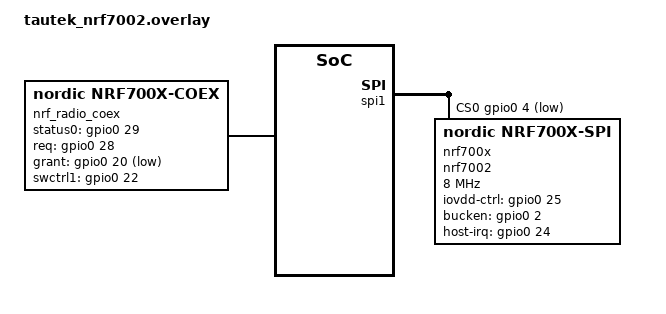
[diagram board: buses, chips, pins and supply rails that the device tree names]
#include <freq.h>

/ {
	nrf_radio_coex: nrf7002-coex {
		status = "okay";
		compatible = "nordic,nrf700x-coex";
		status0-gpios = <&gpio0 29 GPIO_ACTIVE_HIGH>;       /* D2 */
		req-gpios = <&gpio0 28 GPIO_ACTIVE_HIGH>;   /* D3 */
		grant-gpios = <&gpio0 20 (GPIO_PULL_DOWN | GPIO_ACTIVE_LOW)>;    /* D4 */
		swctrl1-gpios = <&gpio0 22 GPIO_ACTIVE_HIGH>;  /* D6 */
	};
};

&spi1 {
	status = "okay";
	cs-gpios = <&gpio0 4 GPIO_ACTIVE_LOW>; /* D10 */

	nrf700x: nrf7002@0 {
		compatible = "nordic,nrf700x-spi";
		status = "okay";
		reg = <0>;
		spi-max-frequency = <DT_FREQ_M(8)>;

		iovdd-ctrl-gpios = <&gpio0 25 (GPIO_ACTIVE_HIGH | GPIO_PULL_DOWN)>;    /* D0 */
		bucken-gpios = <&gpio0 2 (GPIO_ACTIVE_HIGH | GPIO_PULL_DOWN)>;        /* D1 */
		host-irq-gpios = <&gpio0 24 GPIO_ACTIVE_HIGH>;     /* D7 */
	};
};

&gpio_fwd {
	status = "disabled";
};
